VERSION "Elkapod Power Supply CAN Protocol"

NS_ :

BS_:

BU_: ECU

BO_ 101 CAN_ID_GET_ERROR_ACK: 4 ELKAPOD_PSU
    SG_ Error_code : 7|8@0+ (1,0) [0|255] "" ELKAPOD_PSU
    SG_ Data0  : 8|1@0+ (1,0) [0|1] "" ELKAPOD_PSU
    SG_ Data1  : 9|1@0+ (1,0) [0|1] "" ELKAPOD_PSU
    SG_ Data2  : 10|1@0+ (1,0) [0|1] "" ELKAPOD_PSU
    SG_ Data3  : 11|1@0+ (1,0) [0|1] "" ELKAPOD_PSU
    SG_ Data4  : 12|1@0+ (1,0) [0|1] "" ELKAPOD_PSU
    SG_ Data5  : 13|1@0+ (1,0) [0|1] "" ELKAPOD_PSU
    SG_ Data6  : 14|1@0+ (1,0) [0|1] "" ELKAPOD_PSU
    SG_ Data7  : 15|1@0+ (1,0) [0|1] "" ELKAPOD_PSU
    SG_ Data8  : 16|1@0+ (1,0) [0|1] "" ELKAPOD_PSU
    SG_ Data9  : 17|1@0+ (1,0) [0|1] "" ELKAPOD_PSU
    SG_ Data10 : 18|1@0+ (1,0) [0|1] "" ELKAPOD_PSU
    SG_ Data11 : 19|1@0+ (1,0) [0|1] "" ELKAPOD_PSU
    SG_ Data12 : 20|1@0+ (1,0) [0|1] "" ELKAPOD_PSU
    SG_ Data13 : 21|1@0+ (1,0) [0|1] "" ELKAPOD_PSU
    SG_ Data14 : 22|1@0+ (1,0) [0|1] "" ELKAPOD_PSU
    SG_ Data15 : 23|1@0+ (1,0) [0|1] "" ELKAPOD_PSU
    SG_ Data16 : 24|1@0+ (1,0) [0|1] "" ELKAPOD_PSU
    SG_ Data17 : 25|1@0+ (1,0) [0|1] "" ELKAPOD_PSU
    SG_ Data18 : 26|1@0+ (1,0) [0|1] "" ELKAPOD_PSU
    SG_ Data19 : 27|1@0+ (1,0) [0|1] "" ELKAPOD_PSU
    SG_ Data20 : 28|1@0+ (1,0) [0|1] "" ELKAPOD_PSU
    SG_ Data21 : 29|1@0+ (1,0) [0|1] "" ELKAPOD_PSU
    SG_ Data22 : 30|1@0+ (1,0) [0|1] "" ELKAPOD_PSU
    SG_ Data23 : 31|1@0+ (1,0) [0|1] "" ELKAPOD_PSU

BO_ 103 CAN_ID_TRUN_OFF_ACK: 0 ELKAPOD_PSU

BO_ 105 CAN_ID_PRESSED_OFF_BUTTON: 0 ELKAPOD_PSU

BO_ 107 CAN_ID_SET_SERVOS_STATES_ACK: 3 ELKAPOD_PSU
    SG_ Servo1  : 23|1@0+ (1,0) [0|1] "" ELKAPOD_PSU
    SG_ Servo2  : 22|1@0+ (1,0) [0|1] "" ELKAPOD_PSU
    SG_ Servo3  : 21|1@0+ (1,0) [0|1] "" ELKAPOD_PSU
    SG_ Servo4  : 20|1@0+ (1,0) [0|1] "" ELKAPOD_PSU
    SG_ Servo5  : 19|1@0+ (1,0) [0|1] "" ELKAPOD_PSU
    SG_ Servo6  : 18|1@0+ (1,0) [0|1] "" ELKAPOD_PSU
    SG_ Servo7  : 17|1@0+ (1,0) [0|1] "" ELKAPOD_PSU
    SG_ Servo8  : 16|1@0+ (1,0) [0|1] "" ELKAPOD_PSU
    SG_ Servo9  : 15|1@0+ (1,0) [0|1] "" ELKAPOD_PSU
    SG_ Servo10 : 14|1@0+ (1,0) [0|1] "" ELKAPOD_PSU
    SG_ Servo11 : 13|1@0+ (1,0) [0|1] "" ELKAPOD_PSU
    SG_ Servo12 : 12|1@0+ (1,0) [0|1] "" ELKAPOD_PSU
    SG_ Servo13 : 11|1@0+ (1,0) [0|1] "" ELKAPOD_PSU
    SG_ Servo14 : 10|1@0+ (1,0) [0|1] "" ELKAPOD_PSU
    SG_ Servo15 : 9|1@0+ (1,0) [0|1] "" ELKAPOD_PSU
    SG_ Servo16 : 8|1@0+ (1,0) [0|1] "" ELKAPOD_PSU
    SG_ Servo17 : 7|1@0+ (1,0) [0|1] "" ELKAPOD_PSU
    SG_ Servo18 : 6|1@0+ (1,0) [0|1] "" ELKAPOD_PSU

BO_ 109 CAN_ID_SET_MANIP_STATE_REQ: 1 ELKAPOD_PSU
    SG_ MANIP_CONVERTER_STATE   : 7|1@0+ (1,0) [0|1] "" ELKAPOD_PSU

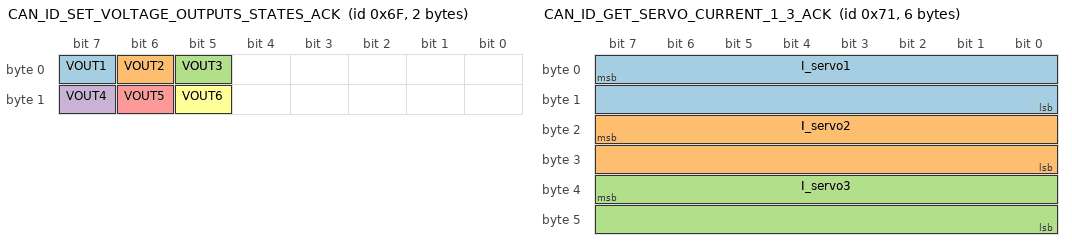
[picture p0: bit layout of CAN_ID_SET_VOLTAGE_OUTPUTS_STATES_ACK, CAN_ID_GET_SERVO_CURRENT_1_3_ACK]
BO_ 111 CAN_ID_SET_VOLTAGE_OUTPUTS_STATES_ACK: 2 ELKAPOD_PSU
    SG_ VOUT1   : 7|1@0+ (1,0) [0|1] "" ELKAPOD_PSU
    SG_ VOUT2   : 6|1@0+ (1,0) [0|1] "" ELKAPOD_PSU
    SG_ VOUT3   : 5|1@0+ (1,0) [0|1] "" ELKAPOD_PSU
    SG_ VOUT4   : 15|1@0+ (1,0) [0|1] "" ELKAPOD_PSU
    SG_ VOUT5   : 14|1@0+ (1,0) [0|1] "" ELKAPOD_PSU
    SG_ VOUT6   : 13|1@0+ (1,0) [0|1] "" ELKAPOD_PSU

BO_ 113 CAN_ID_GET_SERVO_CURRENT_1_3_ACK: 6 ELKAPOD_PSU
    SG_ I_servo1      : 7|16@0+ (1,0) [0|65535] "mA" ELKAPOD_PSU
    SG_ I_servo2      : 23|16@0+ (1,0) [0|65535] "mA" ELKAPOD_PSU
    SG_ I_servo3      : 39|16@0+ (1,0) [0|65535] "mA" ELKAPOD_PSU

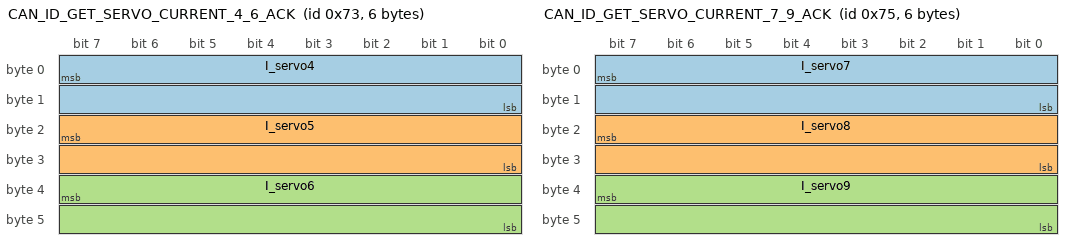
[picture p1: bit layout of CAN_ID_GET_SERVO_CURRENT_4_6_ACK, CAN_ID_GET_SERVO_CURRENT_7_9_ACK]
BO_ 115 CAN_ID_GET_SERVO_CURRENT_4_6_ACK: 6 ELKAPOD_PSU
    SG_ I_servo4      : 7|16@0+ (1,0) [0|65535] "mA" ELKAPOD_PSU
    SG_ I_servo5      : 23|16@0+ (1,0) [0|65535] "mA" ELKAPOD_PSU
    SG_ I_servo6      : 39|16@0+ (1,0) [0|65535] "mA" ELKAPOD_PSU

BO_ 117 CAN_ID_GET_SERVO_CURRENT_7_9_ACK: 6 ELKAPOD_PSU
    SG_ I_servo7      : 7|16@0+ (1,0) [0|65535] "mA" ELKAPOD_PSU
    SG_ I_servo8      : 23|16@0+ (1,0) [0|65535] "mA" ELKAPOD_PSU
    SG_ I_servo9      : 39|16@0+ (1,0) [0|65535] "mA" ELKAPOD_PSU

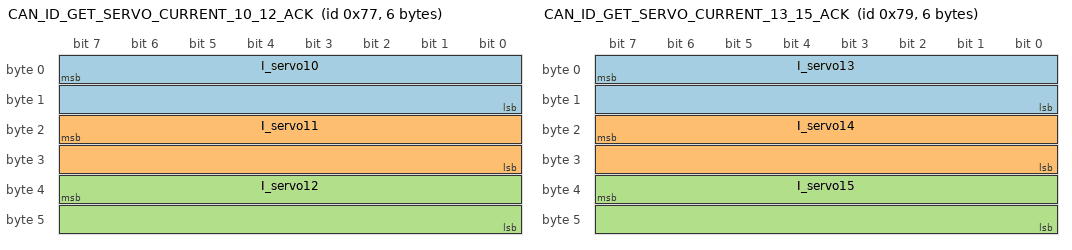
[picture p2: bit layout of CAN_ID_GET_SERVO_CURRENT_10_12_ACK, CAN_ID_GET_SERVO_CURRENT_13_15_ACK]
BO_ 119 CAN_ID_GET_SERVO_CURRENT_10_12_ACK: 6 ELKAPOD_PSU
    SG_ I_servo10     : 7|16@0+ (1,0) [0|65535] "mA" ELKAPOD_PSU
    SG_ I_servo11     : 23|16@0+ (1,0) [0|65535] "mA" ELKAPOD_PSU
    SG_ I_servo12     : 39|16@0+ (1,0) [0|65535] "mA" ELKAPOD_PSU

BO_ 121 CAN_ID_GET_SERVO_CURRENT_13_15_ACK: 6 ELKAPOD_PSU
    SG_ I_servo13     : 7|16@0+ (1,0) [0|65535] "mA" ELKAPOD_PSU
    SG_ I_servo14     : 23|16@0+ (1,0) [0|65535] "mA" ELKAPOD_PSU
    SG_ I_servo15     : 39|16@0+ (1,0) [0|65535] "mA" ELKAPOD_PSU

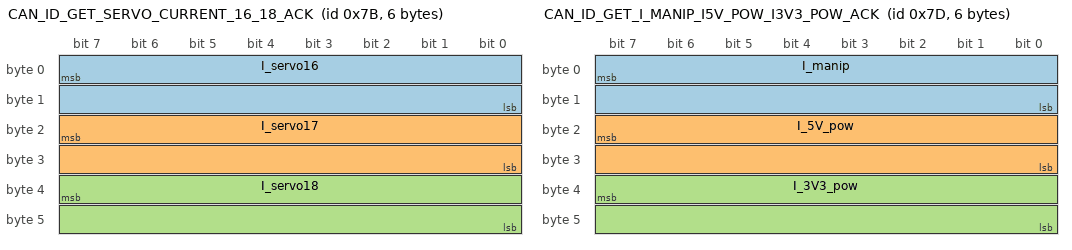
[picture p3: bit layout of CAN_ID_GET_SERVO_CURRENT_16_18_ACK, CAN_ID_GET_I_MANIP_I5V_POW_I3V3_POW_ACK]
BO_ 123 CAN_ID_GET_SERVO_CURRENT_16_18_ACK: 6 ELKAPOD_PSU
    SG_ I_servo16     : 7|16@0+ (1,0) [0|65535] "mA" ELKAPOD_PSU
    SG_ I_servo17     : 23|16@0+ (1,0) [0|65535] "mA" ELKAPOD_PSU
    SG_ I_servo18     : 39|16@0+ (1,0) [0|65535] "mA" ELKAPOD_PSU

BO_ 125 CAN_ID_GET_I_MANIP_I5V_POW_I3V3_POW_ACK: 6 ELKAPOD_PSU
    SG_ I_manip       : 7|16@0+ (1,0) [0|65535] "mA" ELKAPOD_PSU
    SG_ I_5V_pow      : 23|16@0+ (1,0) [0|65535] "mA" ELKAPOD_PSU
    SG_ I_3V3_pow     : 39|16@0+ (1,0) [0|65535] "mA" ELKAPOD_PSU

BO_ 127 CAN_ID_GET_I_STANDBY_I_SUPPLY_ACK: 4 ELKAPOD_PSU
    SG_ I_standby     : 7|16@0+ (1,0) [0|65535] "mA" ELKAPOD_PSU
    SG_ I_supply      : 23|16@0+ (1,0) [0|65535] "mA" ELKAPOD_PSU

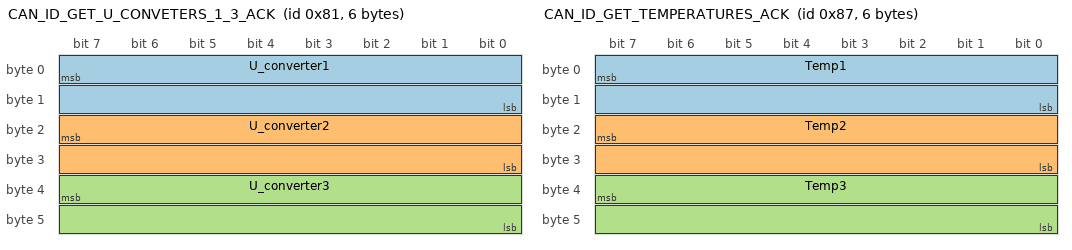
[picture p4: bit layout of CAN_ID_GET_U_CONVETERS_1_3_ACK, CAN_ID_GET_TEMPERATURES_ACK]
BO_ 129 CAN_ID_GET_U_CONVETERS_1_3_ACK: 6 ELKAPOD_PSU
    SG_ U_converter1  : 7|16@0+ (1,0) [0|65535] "mV" ELKAPOD_PSU
    SG_ U_converter2  : 23|16@0+ (1,0) [0|65535] "mV" ELKAPOD_PSU
    SG_ U_converter3  : 39|16@0+ (1,0) [0|65535] "mV" ELKAPOD_PSU

BO_ 131 CAN_ID_GET_U_CONVETERS_4_5_ACK: 4 ELKAPOD_PSU
    SG_ U_converter4  : 7|16@0+ (1,0) [0|65535] "mV" ELKAPOD_PSU
    SG_ U_converter5  : 23|16@0+ (1,0) [0|65535] "mV" ELKAPOD_PSU

BO_ 133 CAN_ID_GET_U_SUPPLY_U_BAT_ACK: 4 ELKAPOD_PSU
    SG_ U_supply      : 7|16@0+ (1,0) [0|65535] "mV" ELKAPOD_PSU
    SG_ U_batt        : 23|16@0+ (1,0) [0|65535] "mV" ELKAPOD_PSU

BO_ 135 CAN_ID_GET_TEMPERATURES_ACK: 6 ELKAPOD_PSU
    SG_ Temp1  : 7|16@0- (1,0) [-32768|32767] "C" ELKAPOD_PSU
    SG_ Temp2  : 23|16@0- (1,0) [-32768|32767] "C" ELKAPOD_PSU
    SG_ Temp3  : 39|16@0- (1,0) [-32768|32767] "C" ELKAPOD_PSU

BO_ 137 CAN_ID_SET_CONVERTER1_VOLTAGE_ACK: 2 ELKAPOD_PSU
    SG_ Converter1_set_voltage  : 7|16@0+ (1,0) [0|65535] "mV" ELKAPOD_PSU

BO_ 139 CAN_ID_SET_CONVERTER2_VOLTAGE_ACK: 2 ELKAPOD_PSU
    SG_ Converter2_set_voltage  : 7|16@0+ (1,0) [0|65535] "mV" ELKAPOD_PSU

BO_ 141 CAN_ID_SET_CONVERTER3_VOLTAGE_ACK: 2 ELKAPOD_PSU
    SG_ Converter3_set_voltage  : 7|16@0+ (1,0) [0|65535] "mV" ELKAPOD_PSU

BO_ 143 CAN_ID_SET_CONVERTER4_VOLTAGE_ACK: 2 ELKAPOD_PSU
    SG_ Converter4_set_voltage  : 7|16@0+ (1,0) [0|65535] "mV" ELKAPOD_PSU

BO_ 151 CAN_ID_SERVICE_CLR_ERROR_ACK: 0 ELKAPOD_PSU
